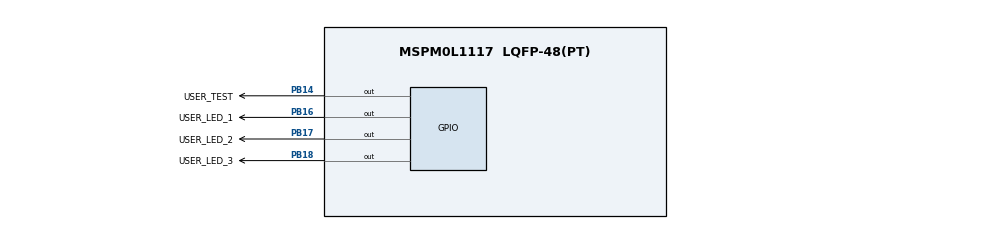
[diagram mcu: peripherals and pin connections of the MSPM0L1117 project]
//@cliArgs --device "MSPM0L111X" --package "LQFP-48(PT)" --part "Default"
//@v2CliArgs --device "MSPM0L1117" --package "LQFP-48(PT)"
// @cliArgs --board /ti/boards/LP_MSPM0L1117 --rtos nortos

/**
 * Import the modules used in this configuration.
 */
const GPIO   = scripting.addModule("/ti/driverlib/GPIO", {}, false);
const GPIO1  = GPIO.addInstance();

/**
 * Write custom configuration values to the imported modules.
 */

GPIO1.$name                         = "GPIO_LEDS";
GPIO1.port                          = "PORTB";
GPIO1.associatedPins.create(4);
GPIO1.associatedPins[0].$name       = "USER_LED_1";
GPIO1.associatedPins[0].assignedPin = "16";
GPIO1.associatedPins[0].pin.$assign = "PB16";
GPIO1.associatedPins[1].$name       = "USER_LED_2";
GPIO1.associatedPins[1].assignedPin = "17";
GPIO1.associatedPins[1].pin.$assign = "PB17";
GPIO1.associatedPins[2].$name       = "USER_LED_3";
GPIO1.associatedPins[2].assignedPin = "18";
GPIO1.associatedPins[2].pin.$assign = "PB18";
GPIO1.associatedPins[3].$name       = "USER_TEST";
GPIO1.associatedPins[3].pin.$assign = "PB14";

const Board = scripting.addModule("/ti/driverlib/Board", {}, false);
const SYSCTL = scripting.addModule("/ti/driverlib/SYSCTL");

SYSCTL.clockTreeEn = true;
